AUTOSAR XML (schema 4.0)
package /YourProjectName
  ecu configuration EcuConfig: ecu-name=YourECUName, processor=ARM_CORTEX_M4, clock=core-clock=80000000, memory={flash-size=512, ram-size=128}
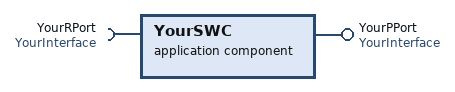
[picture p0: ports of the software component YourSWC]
  application sw component type YourSWC
    provide port YourPPort: provided-interface=YourInterface
    require port YourRPort: required-interface=YourInterface
  sender receiver interface YourInterface
    data YourDataElement: type=Uint8Type
  impl type Uint8Type: category=VALUE, base-type=Uint8BaseType
  base type Uint8BaseType: base-type-definition={base-type-size=8, base-type-encoding=NONE}
